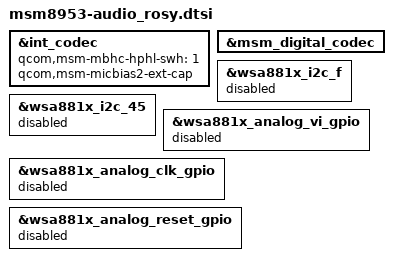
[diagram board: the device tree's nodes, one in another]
&int_codec {
	qcom,msm-mbhc-hphl-swh = <1>;
	qcom,msm-micbias2-ext-cap;

	/delete-property/ qcom,cdc-us-euro-gpios;
	/delete-property/ asoc-wsa-codec-names;
	/delete-property/ asoc-wsa-codec-prefixes;
	/delete-property/ msm-vdd-wsa-switch-supply;
	/delete-property/ qcom,msm-vdd-wsa-switch-voltage;
	/delete-property/ qcom,msm-vdd-wsa-switch-current;
};

&msm_digital_codec {
	status = "ok";
};

&wsa881x_i2c_f {
        status = "disabled";
};

&wsa881x_i2c_45 {
        status = "disabled";
};

&wsa881x_analog_vi_gpio {
        status = "disabled";
};

&wsa881x_analog_clk_gpio {
        status = "disabled";
};

&wsa881x_analog_reset_gpio {
        status = "disabled";
};
